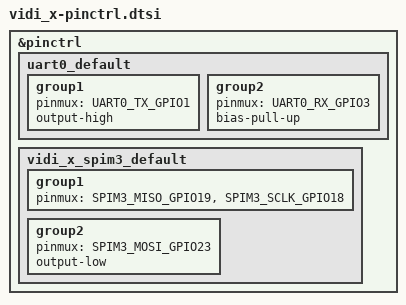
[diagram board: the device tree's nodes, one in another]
/*
 * Copyright (c) 2022-2025 Espressif Systems (Shanghai) Co., Ltd.
 * SPDX-FileCopyrightText: 2026 Dejan R.
 * SPDX-License-Identifier: Apache-2.0
 *
 * VIDI X v1.0 pin configuration.
 * Adapted from Zephyr's ESP32-DevKitC pin configuration.
 */
#include <zephyr/dt-bindings/pinctrl/esp-pinctrl-common.h>
#include <zephyr/dt-bindings/pinctrl/esp32-pinctrl.h>
#include <zephyr/dt-bindings/pinctrl/esp32-gpio-sigmap.h>

&pinctrl {
    uart0_default: uart0_default {
        group1 {
            pinmux = <UART0_TX_GPIO1>;
            output-high;
        };
        group2 {
            pinmux = <UART0_RX_GPIO3>;
            bias-pull-up;
        };
    };

    vidi_x_spim3_default: vidi_x_spim3_default {
        group1 {
            pinmux = <SPIM3_MISO_GPIO19>,
                     <SPIM3_SCLK_GPIO18>;
        };
        group2 {
            pinmux = <SPIM3_MOSI_GPIO23>;
            output-low;
        };
    };
};
